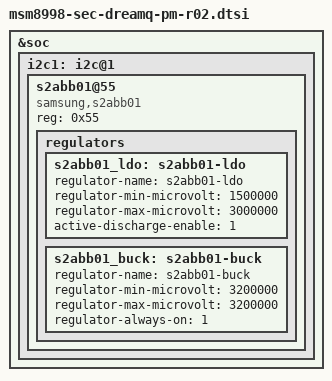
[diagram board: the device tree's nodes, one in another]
/* Copyright (c) 2014, The Linux Foundation. All rights reserved.
 *
 * This program is free software; you can redistribute it and/or modify
 * it under the terms of the GNU General Public License version 2 and
 * only version 2 as published by the Free Software Foundation.
 *
 * This program is distributed in the hope that it will be useful,
 * but WITHOUT ANY WARRANTY; without even the implied warranty of
 * MERCHANTABILITY or FITNESS FOR A PARTICULAR PURPOSE.  See the
 * GNU General Public License for more details.
 */

&soc {
	i2c1: i2c@1 {
		/* S2ABB01 BuckBoost PMIC */
		s2abb01@55 {
			compatible = "samsung,s2abb01";
			reg = <0x55>;

			regulators {
				s2abb01_ldo: s2abb01-ldo {
					regulator-name = "s2abb01-ldo";
					regulator-min-microvolt = <1500000>;
					regulator-max-microvolt = <3000000>;
					active-discharge-enable = <1>;
				};

				/* TODO: need to fix voltage to 3.5V */
				/* TODO: state in suspend */
				s2abb01_buck: s2abb01-buck {
					regulator-name = "s2abb01-buck";
					regulator-min-microvolt = <3200000>;
					regulator-max-microvolt = <3200000>;
					regulator-always-on = <1>;
				};
			};
		};
	};
};
